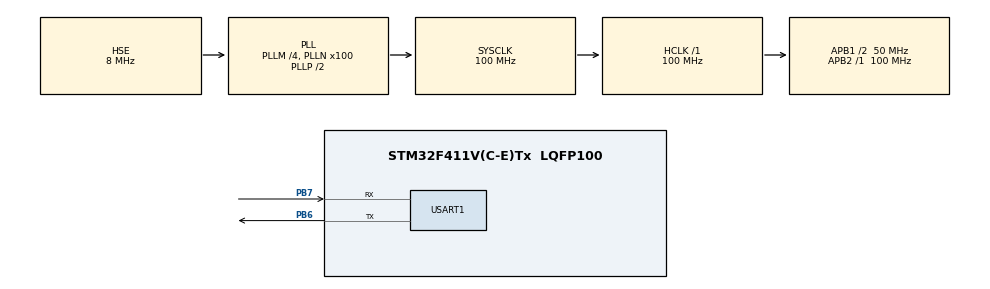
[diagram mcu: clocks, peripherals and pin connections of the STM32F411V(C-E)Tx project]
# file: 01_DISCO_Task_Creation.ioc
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FREERTOS.Tasks01=defaultTask,24,128,StartDefaultTask,Default,NULL,Dynamic,NULL,NULL
Mcu.Family=STM32F4
Mcu.Name=STM32F411V(C-E)Tx
Mcu.Package=LQFP100
NVIC.PriorityGroup=NVIC_PRIORITYGROUP_4
NVIC.TIM1_UP_TIM10_IRQn=true\:15\:0\:false\:false\:true\:false\:false\:true\:true
NVIC.TimeBase=TIM1_UP_TIM10_IRQn
NVIC.TimeBaseIP=TIM1
PA13.GPIO_Label=SWDIO
PA13.Mode=Serial_Wire
PA13.Signal=SYS_JTMS-SWDIO
PA14.GPIO_Label=SWCLK
PA14.Mode=Serial_Wire
PA14.Signal=SYS_JTCK-SWCLK
PB3.GPIO_Label=SWO
PB3.Signal=SYS_JTDO-SWO
PB6.Mode=Asynchronous
PB6.Signal=USART1_TX
PB7.Mode=Asynchronous
PB7.Signal=USART1_RX
PH0\ -\ OSC_IN.GPIO_Label=PH0-OSC_IN
PH0\ -\ OSC_IN.Mode=HSE-External-Oscillator
PH0\ -\ OSC_IN.Signal=RCC_OSC_IN
PH1\ -\ OSC_OUT.GPIO_Label=PH1-OSC_OUT
PH1\ -\ OSC_OUT.Mode=HSE-External-Oscillator
PH1\ -\ OSC_OUT.Signal=RCC_OSC_OUT
ProjectManager.HeapSize=0x200
ProjectManager.StackSize=0x400
ProjectManager.TargetToolchain=STM32CubeIDE
RCC.48MHZClocksFreq_Value=25000000
RCC.AHBFreq_Value=100000000
RCC.APB1CLKDivider=RCC_HCLK_DIV2
RCC.APB1Freq_Value=50000000
RCC.APB1TimFreq_Value=100000000
RCC.APB2Freq_Value=100000000
RCC.APB2TimFreq_Value=100000000
RCC.CortexFreq_Value=100000000
RCC.HCLKFreq_Value=100000000
RCC.HSE_VALUE=8000000
RCC.HSI_VALUE=16000000
RCC.PLLI2SM=5
RCC.PLLI2SN=200
RCC.PLLM=4
RCC.PLLN=100
RCC.PLLQ=8
RCC.PLLSourceVirtual=RCC_PLLSOURCE_HSE
RCC.SYSCLKFreq_VALUE=100000000
RCC.SYSCLKSource=RCC_SYSCLKSOURCE_PLLCLK
RCC.VCOOutputFreq_Value=200000000
USART1.VirtualMode=VM_ASYNC
VP_FREERTOS_VS_CMSIS_V2.Mode=CMSIS_V2
VP_SYS_VS_tim1.Mode=TIM1
board=STM32F411E-DISCO

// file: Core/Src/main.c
/* USER CODE BEGIN Header */
/**
  ******************************************************************************
  * @file           : main.c
  * @brief          : Main program body
  ******************************************************************************
  * @attention
  *
  * Copyright (c) 2023 STMicroelectronics.
  * All rights reserved.
  *
  * This software is licensed under terms that can be found in the LICENSE file
  * in the root directory of this software component.
  * If no LICENSE file comes with this software, it is provided AS-IS.
  *
  ******************************************************************************
  */
/* USER CODE END Header */
#include "main.h"
#include "cmsis_os.h"

/* USER CODE BEGIN Includes */
#include "stdio.h"
#include "stdbool.h"
/* USER CODE END Includes */

/* USER CODE BEGIN PTD */
typedef uint32_t TaskProfiler;
/* USER CODE END PTD */

/* USER CODE BEGIN PD */
#define STACK_SIZE 512
#define LOOP_DELAY 200000
#define MS_DELAY 100
/* USER CODE END PD */

UART_HandleTypeDef huart1;

/* Definitions for defaultTask */
//osThreadId_t defaultTaskHandle;
//const osThreadAttr_t defaultTask_attributes = {
//  .name = "defaultTask",
//  .stack_size = 128 * 4,
//  .priority = (osPriority_t) osPriorityNormal,
//};
/* USER CODE BEGIN PV */
TaskProfiler BlueTaskProfiler;
TaskProfiler RedTaskProfiler;
TaskProfiler GreenTaskProfiler;
TaskProfiler OrangeTaskProfiler;
TaskProfiler Timer1Profiler;
TaskProfiler Timer2Profiler;

osThreadId_t red_id;
osThreadId_t blue_id;
osThreadId_t green_id;
osThreadId_t orange_id;

osTimerId_t timer_1_id, timer_2_id;

//const osSemaphoreAttr_t uartSemAttribs = {
//		.name = "UART Semaphore"
//};

const osMutexAttr_t uartMutexAttribs = {
		.name = "UART Mutex"
};

//osSemaphoreId_t uart_sem_id;

osMutexId_t uart_mut_id;
/* USER CODE END PV */

void SystemClock_Config(void);
static void MX_GPIO_Init(void);
static void MX_USART1_UART_Init(void);
//void StartDefaultTask(void *argument);

/* USER CODE BEGIN PFP */
void vGreenLedControllerTask(void * pvParameters);
void vRedLedControllerTask(void * pvParameters);
void vBlueLedControllerTask(void * pvParameters);
void vOrangeLedControllerTask(void * pvParameters);
void Timer1_Callback (void * arg);
void Timer2_Callback (void * arg);
int uart1_write(int ch);
int __io_putchar(int ch);
/* USER CODE END PFP */

int main(void)
{

  /* MCU Configuration--------------------------------------------------------*/

  /* Reset of all peripherals, Initializes the Flash interface and the Systick. */
  HAL_Init();

  /* Configure the system clock */
  SystemClock_Config();

  /* Initialize all configured peripherals */
  MX_GPIO_Init();
  MX_USART1_UART_Init();
  /* USER CODE BEGIN 2 */
	osKernelInitialize();

	osThreadAttr_t greenThreadAttribs = {
						.name = "GreenTask",
						.stack_size = STACK_SIZE,
						.priority = osPriorityNormal
						};
	osThreadAttr_t redThreadAttribs = {
						.name = "redTask",
						.stack_size = STACK_SIZE,
						.priority = osPriorityNormal
						};
	osThreadAttr_t blueThreadAttribs = {
						.name = "blueTask",
						.stack_size = STACK_SIZE,
						.priority = osPriorityNormal
						};
	osThreadAttr_t orangeThreadAttribs = {
						.name = "orangeTask",
						.stack_size = STACK_SIZE,
						.priority = osPriorityNormal
						};

	green_id = osThreadNew(vGreenLedControllerTask, NULL, &greenThreadAttribs);
	red_id = osThreadNew(vRedLedControllerTask, NULL, &redThreadAttribs);
	blue_id = osThreadNew(vBlueLedControllerTask, NULL, &blueThreadAttribs);
	orange_id = osThreadNew(vOrangeLedControllerTask, NULL, &orangeThreadAttribs);

	timer_1_id = osTimerNew(Timer1_Callback, osTimerOnce, NULL, NULL);
	timer_2_id = osTimerNew(Timer2_Callback, osTimerPeriodic, NULL, NULL);

//	uart_sem_id = osSemaphoreNew(1, 1, &uartSemAttribs);
	uart_mut_id = osMutexNew(&uartMutexAttribs);

	osKernelStart();
  /* USER CODE END 2 */

  /* Init scheduler */
  //osKernelInitialize();

  /* Create the thread(s) */
  /* creation of defaultTask */
  //defaultTaskHandle = osThreadNew(StartDefaultTask, NULL, &defaultTask_attributes);

  /* Start scheduler */
  //osKernelStart();

  /* We should never get here as control is now taken by the scheduler */
  /* Infinite loop */
  while (1)
  {

  }
}

void SystemClock_Config(void)
{
  RCC_OscInitTypeDef RCC_OscInitStruct = {0};
  RCC_ClkInitTypeDef RCC_ClkInitStruct = {0};

  /** Configure the main internal regulator output voltage
  */
  __HAL_RCC_PWR_CLK_ENABLE();
  __HAL_PWR_VOLTAGESCALING_CONFIG(PWR_REGULATOR_VOLTAGE_SCALE1);

  /** Initializes the RCC Oscillators according to the specified parameters
  * in the RCC_OscInitTypeDef structure.
  */
  RCC_OscInitStruct.OscillatorType = RCC_OSCILLATORTYPE_HSE;
  RCC_OscInitStruct.HSEState = RCC_HSE_ON;
  RCC_OscInitStruct.PLL.PLLState = RCC_PLL_ON;
  RCC_OscInitStruct.PLL.PLLSource = RCC_PLLSOURCE_HSE;
  RCC_OscInitStruct.PLL.PLLM = 4;
  RCC_OscInitStruct.PLL.PLLN = 100;
  RCC_OscInitStruct.PLL.PLLP = RCC_PLLP_DIV2;
  RCC_OscInitStruct.PLL.PLLQ = 8;
  if (HAL_RCC_OscConfig(&RCC_OscInitStruct) != HAL_OK)
  {
    Error_Handler();
  }

  /** Initializes the CPU, AHB and APB buses clocks
  */
  RCC_ClkInitStruct.ClockType = RCC_CLOCKTYPE_HCLK|RCC_CLOCKTYPE_SYSCLK
                              |RCC_CLOCKTYPE_PCLK1|RCC_CLOCKTYPE_PCLK2;
  RCC_ClkInitStruct.SYSCLKSource = RCC_SYSCLKSOURCE_PLLCLK;
  RCC_ClkInitStruct.AHBCLKDivider = RCC_SYSCLK_DIV1;
  RCC_ClkInitStruct.APB1CLKDivider = RCC_HCLK_DIV2;
  RCC_ClkInitStruct.APB2CLKDivider = RCC_HCLK_DIV1;

  if (HAL_RCC_ClockConfig(&RCC_ClkInitStruct, FLASH_LATENCY_3) != HAL_OK)
  {
    Error_Handler();
  }
}

static void MX_USART1_UART_Init(void)
{

  huart1.Instance = USART1;
  huart1.Init.BaudRate = 115200;
  huart1.Init.WordLength = UART_WORDLENGTH_8B;
  huart1.Init.StopBits = UART_STOPBITS_1;
  huart1.Init.Parity = UART_PARITY_NONE;
  huart1.Init.Mode = UART_MODE_TX_RX;
  huart1.Init.HwFlowCtl = UART_HWCONTROL_NONE;
  huart1.Init.OverSampling = UART_OVERSAMPLING_16;
  if (HAL_UART_Init(&huart1) != HAL_OK)
  {
    Error_Handler();
  }

}

static void MX_GPIO_Init(void)
{

  /* GPIO Ports Clock Enable */
  __HAL_RCC_GPIOH_CLK_ENABLE();
  __HAL_RCC_GPIOA_CLK_ENABLE();
  __HAL_RCC_GPIOB_CLK_ENABLE();

}

/* USER CODE BEGIN 4 */
void vGreenLedControllerTask(void * pvParameters)
{
	while(1)
	{
		GreenTaskProfiler++;
		//		osSemaphoreAcquire(uart_sem_id, osWaitForever);
				osMutexAcquire(uart_mut_id, osWaitForever);
				printf("This is GREEN Task\r\n");
		//		osSemaphoreRelease(uart_sem_id);
				osMutexRelease(uart_mut_id);
		osDelay(100);
	}
}

void vRedLedControllerTask(void * pvParameters)
{
	while(1)
	{
		RedTaskProfiler++;
		//		osSemaphoreAcquire(uart_sem_id, osWaitForever);
				osMutexAcquire(uart_mut_id, osWaitForever);
				printf("This is RED Task\r\n");
		//		osSemaphoreRelease(uart_sem_id);
				osMutexRelease(uart_mut_id);
		osDelay(100);
	}
}

void vBlueLedControllerTask(void * pvParameters)
{
	while(1)
	{
		BlueTaskProfiler++;

//		osSemaphoreAcquire(uart_sem_id, osWaitForever);
		osMutexAcquire(uart_mut_id, osWaitForever);
		printf("This is BLUE Task\r\n");
//		osSemaphoreRelease(uart_sem_id);
		osMutexRelease(uart_mut_id);

		osDelay(100);
	}
}

void vOrangeLedControllerTask(void * pvParameters)
{
	osTimerStart(timer_1_id, 5000);
	osTimerStart(timer_2_id, 1000);
	while(1)
	{
		OrangeTaskProfiler++;
		//		osSemaphoreAcquire(uart_sem_id, osWaitForever);
				osMutexAcquire(uart_mut_id, osWaitForever);
				printf("This is ORANGE Task\r\n");
		//		osSemaphoreRelease(uart_sem_id);
				osMutexRelease(uart_mut_id);
		osDelay(100);
	}
}

void Timer1_Callback (void * arg)
{
	Timer1Profiler++;
}

void Timer2_Callback (void * arg)
{
	Timer2Profiler++;
}

int uart1_write(int ch)
{
	while(!(USART1->SR & 0x0080)) {}
	USART1->DR = (ch & 0xFF);
	return ch;
}

int __io_putchar(int ch)
{
	uart1_write(ch);
	return ch;
}
/* USER CODE END 4 */

//void StartDefaultTask(void *argument)
//{
//  /* USER CODE BEGIN 5 */
//  /* Infinite loop */
//  for(;;)
//  {
//    osDelay(1);
//  }
//  /* USER CODE END 5 */
//}

void HAL_TIM_PeriodElapsedCallback(TIM_HandleTypeDef *htim)
{
  if (htim->Instance == TIM1) {
    HAL_IncTick();
  }
}

void Error_Handler(void)
{
  __disable_irq();
  while (1)
  {
  }
}
